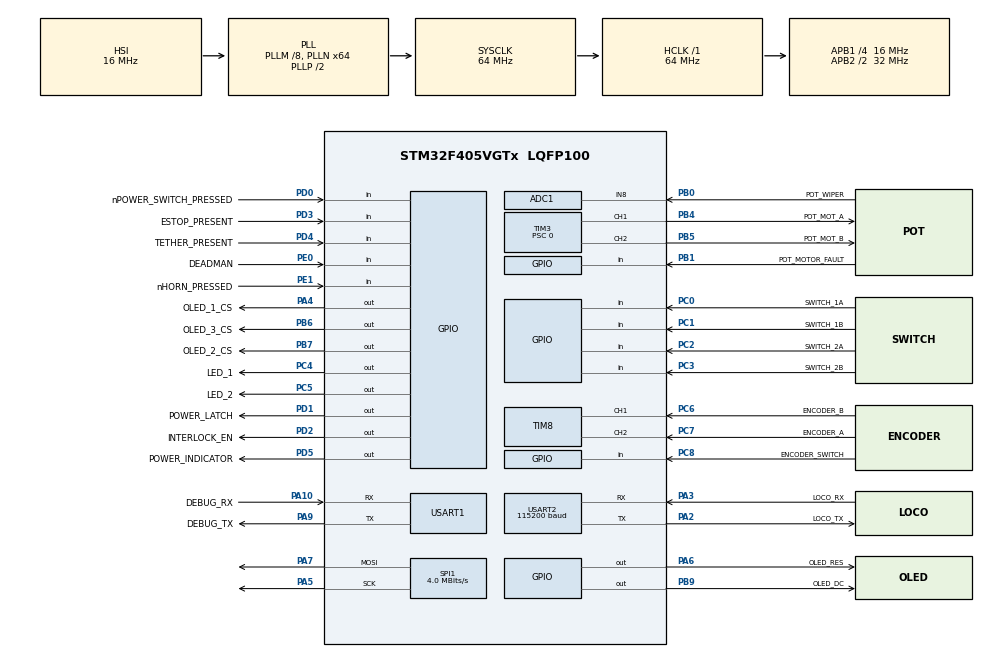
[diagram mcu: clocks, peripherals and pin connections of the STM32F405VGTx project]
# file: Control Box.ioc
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ADC1.Channel-0\#ChannelRegularConversion=ADC_CHANNEL_8
ADC1.ContinuousConvMode=ENABLE
ADC1.EOCSelection=ADC_EOC_SEQ_CONV
ADC1.NbrOfConversionFlag=1
ADC1.Rank-0\#ChannelRegularConversion=1
ADC1.SamplingTime-0\#ChannelRegularConversion=ADC_SAMPLETIME_3CYCLES
ADC1.master=1
Mcu.Family=STM32F4
Mcu.Name=STM32F405VGTx
Mcu.Package=LQFP100
NVIC.PriorityGroup=NVIC_PRIORITYGROUP_4
NVIC.USART1_IRQn=true\:0\:0\:false\:false\:true\:true\:true
NVIC.USART2_IRQn=true\:0\:0\:false\:false\:true\:true\:true
PA10.GPIO_Label=DEBUG_RX
PA10.Mode=Asynchronous
PA10.Signal=USART1_RX
PA2.GPIO_Label=LOCO_TX
PA2.Mode=Asynchronous
PA2.Signal=USART2_TX
PA3.GPIO_Label=LOCO_RX
PA3.Mode=Asynchronous
PA3.Signal=USART2_RX
PA4.GPIO_Label=OLED_1_CS
PA4.GPIO_PuPd=GPIO_NOPULL
PA4.PinState=GPIO_PIN_SET
PA4.Signal=GPIO_Output
PA5.Mode=TX_Only_Simplex_Unidirect_Master
PA5.Signal=SPI1_SCK
PA6.GPIO_Label=OLED_RES
PA6.GPIO_PuPd=GPIO_NOPULL
PA6.Signal=GPIO_Output
PA7.Mode=TX_Only_Simplex_Unidirect_Master
PA7.Signal=SPI1_MOSI
PA9.GPIO_Label=DEBUG_TX
PA9.Mode=Asynchronous
PA9.Signal=USART1_TX
PB0.GPIO_Label=POT_WIPER
PB0.Signal=SharedAnalog_PB0
PB1.GPIO_Label=POT_MOTOR_FAULT
PB1.Signal=GPIO_Input
PB4.GPIO_Label=POT_MOT_A
PB4.Signal=S_TIM3_CH1
PB5.GPIO_Label=POT_MOT_B
PB5.Signal=S_TIM3_CH2
PB6.GPIO_Label=OLED_3_CS
PB6.Signal=GPIO_Output
PB7.GPIO_Label=OLED_2_CS
PB7.Signal=GPIO_Output
PB9.GPIO_Label=OLED_DC
PB9.Signal=GPIO_Output
PC0.GPIO_Label=SWITCH_1A
PC0.Signal=GPIO_Input
PC1.GPIO_Label=SWITCH_1B
PC1.Signal=GPIO_Input
PC2.GPIO_Label=SWITCH_2A
PC2.Signal=GPIO_Input
PC3.GPIO_Label=SWITCH_2B
PC3.Signal=GPIO_Input
PC4.GPIO_Label=LED_1
PC4.Signal=GPIO_Output
PC5.GPIO_Label=LED_2
PC5.Signal=GPIO_Output
PC6.GPIO_Label=ENCODER_B
PC6.Signal=S_TIM8_CH1
PC7.GPIO_Label=ENCODER_A
PC7.Signal=S_TIM8_CH2
PC8.GPIO_Label=ENCODER_SWITCH
PC8.Signal=GPIO_Input
PD0.GPIO_Label=nPOWER_SWITCH_PRESSED
PD0.Signal=GPIO_Input
PD1.GPIO_Label=POWER_LATCH
PD1.Signal=GPIO_Output
PD2.GPIO_Label=INTERLOCK_EN
PD2.PinState=GPIO_PIN_RESET
PD2.Signal=GPIO_Output
PD3.GPIO_Label=ESTOP_PRESENT
PD3.Signal=GPIO_Input
PD4.GPIO_Label=TETHER_PRESENT
PD4.Signal=GPIO_Input
PD5.GPIO_Label=POWER_INDICATOR
PD5.Signal=GPIO_Output
PE0.GPIO_Label=DEADMAN
PE0.Signal=GPIO_Input
PE1.GPIO_Label=nHORN_PRESSED
PE1.Signal=GPIO_Input
ProjectManager.HeapSize=0x200
ProjectManager.StackSize=0x400
ProjectManager.TargetToolchain=STM32CubeIDE
RCC.48MHZClocksFreq_Value=32000000
RCC.AHBFreq_Value=64000000
RCC.APB1CLKDivider=RCC_HCLK_DIV4
RCC.APB1Freq_Value=16000000
RCC.APB1TimFreq_Value=32000000
RCC.APB2CLKDivider=RCC_HCLK_DIV2
RCC.APB2Freq_Value=32000000
RCC.APB2TimFreq_Value=64000000
RCC.CortexFreq_Value=64000000
RCC.HCLKFreq_Value=64000000
RCC.HSE_VALUE=25000000
RCC.HSI_VALUE=16000000
RCC.LSE_VALUE=32768
RCC.PLLM=8
RCC.PLLN=64
RCC.SYSCLKFreq_VALUE=64000000
RCC.SYSCLKSource=RCC_SYSCLKSOURCE_PLLCLK
RCC.VCOOutputFreq_Value=128000000
SH.S_TIM3_CH1.0=TIM3_CH1,PWM Generation1 CH1
SH.S_TIM3_CH2.0=TIM3_CH2,PWM Generation2 CH2
SH.S_TIM8_CH1.0=TIM8_CH1,Encoder_Interface
SH.S_TIM8_CH2.0=TIM8_CH2,Encoder_Interface
SH.SharedAnalog_PB0.0=GPIO_Analog
SH.SharedAnalog_PB0.1=ADC1_IN8,IN8
SPI1.BaudRatePrescaler=SPI_BAUDRATEPRESCALER_8
SPI1.CLKPhase=SPI_PHASE_1EDGE
SPI1.CalculateBaudRate=4.0 MBits/s
SPI1.Direction=SPI_DIRECTION_2LINES
SPI1.Mode=SPI_MODE_MASTER
SPI1.VirtualType=VM_MASTER
TIM3.AutoReloadPreload=TIM_AUTORELOAD_PRELOAD_DISABLE
TIM3.Channel-PWM\ Generation1\ CH1=TIM_CHANNEL_1
TIM3.Channel-PWM\ Generation2\ CH2=TIM_CHANNEL_2
TIM3.OCMode_PWM-PWM\ Generation1\ CH1=TIM_OCMODE_PWM1
TIM3.OCMode_PWM-PWM\ Generation2\ CH2=TIM_OCMODE_PWM1
TIM3.OCPolarity_1=TIM_OCPOLARITY_HIGH
TIM3.Period=4095
TIM3.Prescaler=0
TIM8.EncoderMode=TIM_ENCODERMODE_TI12
TIM8.IC1Filter=0
TIM8.IC1Polarity=TIM_ICPOLARITY_FALLING
TIM8.IC2Filter=0
TIM8.IC2Polarity=TIM_ICPOLARITY_RISING
USART1.VirtualMode=VM_ASYNC
USART2.BaudRate=115200
USART2.VirtualMode=VM_ASYNC
board=custom

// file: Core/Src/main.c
/* USER CODE BEGIN Header */
/**
 ******************************************************************************
 * @file           : main.c
 * @brief          : Main program body
 ******************************************************************************
 * @attention
 *
 * <h2><center>&copy; Copyright (c) 2021 STMicroelectronics.
 * All rights reserved.</center></h2>
 *
 * This software component is licensed by ST under BSD 3-Clause license,
 * the "License"; You may not use this file except in compliance with the
 * License. You may obtain a copy of the License at:
 *                        opensource.org/licenses/BSD-3-Clause
 *
 ******************************************************************************
 */
/* USER CODE END Header */
#include "main.h"

/* USER CODE BEGIN Includes */
#include "controlbox.hpp"
/* USER CODE END Includes */

ADC_HandleTypeDef hadc1;

SPI_HandleTypeDef hspi1;

TIM_HandleTypeDef htim3;
TIM_HandleTypeDef htim8;

UART_HandleTypeDef huart1;
UART_HandleTypeDef huart2;

void SystemClock_Config(void);
static void MX_GPIO_Init(void);
static void MX_SPI1_Init(void);
static void MX_TIM8_Init(void);
static void MX_ADC1_Init(void);
static void MX_USART2_UART_Init(void);
static void MX_TIM3_Init(void);
static void MX_USART1_UART_Init(void);

int main(void)
{

  /* MCU Configuration--------------------------------------------------------*/

  /* Reset of all peripherals, Initializes the Flash interface and the Systick. */
  HAL_Init();

  /* Configure the system clock */
  SystemClock_Config();

  /* Initialize all configured peripherals */
  MX_GPIO_Init();
  MX_SPI1_Init();
  MX_TIM8_Init();
  MX_ADC1_Init();
  MX_USART2_UART_Init();
  MX_TIM3_Init();
  MX_USART1_UART_Init();
  /* USER CODE BEGIN 2 */
	HAL_ADC_Start(&hadc1);

	HAL_TIM_Encoder_Start(&htim8, TIM_CHANNEL_ALL);

	HAL_TIM_PWM_Start(&htim3, TIM_CHANNEL_1);
	HAL_TIM_PWM_Start(&htim3, TIM_CHANNEL_2);

	init_input(&hadc1, &htim3);
	init_displays(&hspi1);
	init_modules(&huart2);

	control_box();
  /* USER CODE END 2 */

  /* Infinite loop */
	while (1) {

    /* USER CODE BEGIN 3 */
		// We shouldn't end up here unless something has gone wrong
		HAL_GPIO_WritePin(LED_2_GPIO_Port, LED_2_Pin, (GPIO_PinState) 1);
		HAL_Delay(500);
		HAL_GPIO_WritePin(LED_2_GPIO_Port, LED_2_Pin, (GPIO_PinState) 0);
		HAL_Delay(500);
	}
  /* USER CODE END 3 */
}

void SystemClock_Config(void)
{
  RCC_OscInitTypeDef RCC_OscInitStruct = {0};
  RCC_ClkInitTypeDef RCC_ClkInitStruct = {0};

  /** Configure the main internal regulator output voltage
  */
  __HAL_RCC_PWR_CLK_ENABLE();
  __HAL_PWR_VOLTAGESCALING_CONFIG(PWR_REGULATOR_VOLTAGE_SCALE1);
  /** Initializes the RCC Oscillators according to the specified parameters
  * in the RCC_OscInitTypeDef structure.
  */
  RCC_OscInitStruct.OscillatorType = RCC_OSCILLATORTYPE_HSI;
  RCC_OscInitStruct.HSIState = RCC_HSI_ON;
  RCC_OscInitStruct.HSICalibrationValue = RCC_HSICALIBRATION_DEFAULT;
  RCC_OscInitStruct.PLL.PLLState = RCC_PLL_ON;
  RCC_OscInitStruct.PLL.PLLSource = RCC_PLLSOURCE_HSI;
  RCC_OscInitStruct.PLL.PLLM = 8;
  RCC_OscInitStruct.PLL.PLLN = 64;
  RCC_OscInitStruct.PLL.PLLP = RCC_PLLP_DIV2;
  RCC_OscInitStruct.PLL.PLLQ = 4;
  if (HAL_RCC_OscConfig(&RCC_OscInitStruct) != HAL_OK)
  {
    Error_Handler();
  }
  /** Initializes the CPU, AHB and APB buses clocks
  */
  RCC_ClkInitStruct.ClockType = RCC_CLOCKTYPE_HCLK|RCC_CLOCKTYPE_SYSCLK
                              |RCC_CLOCKTYPE_PCLK1|RCC_CLOCKTYPE_PCLK2;
  RCC_ClkInitStruct.SYSCLKSource = RCC_SYSCLKSOURCE_PLLCLK;
  RCC_ClkInitStruct.AHBCLKDivider = RCC_SYSCLK_DIV1;
  RCC_ClkInitStruct.APB1CLKDivider = RCC_HCLK_DIV4;
  RCC_ClkInitStruct.APB2CLKDivider = RCC_HCLK_DIV2;

  if (HAL_RCC_ClockConfig(&RCC_ClkInitStruct, FLASH_LATENCY_2) != HAL_OK)
  {
    Error_Handler();
  }
}

static void MX_ADC1_Init(void)
{

  ADC_ChannelConfTypeDef sConfig = {0};

  /** Configure the global features of the ADC (Clock, Resolution, Data Alignment and number of conversion)
  */
  hadc1.Instance = ADC1;
  hadc1.Init.ClockPrescaler = ADC_CLOCK_SYNC_PCLK_DIV2;
  hadc1.Init.Resolution = ADC_RESOLUTION_12B;
  hadc1.Init.ScanConvMode = DISABLE;
  hadc1.Init.ContinuousConvMode = ENABLE;
  hadc1.Init.DiscontinuousConvMode = DISABLE;
  hadc1.Init.ExternalTrigConvEdge = ADC_EXTERNALTRIGCONVEDGE_NONE;
  hadc1.Init.ExternalTrigConv = ADC_SOFTWARE_START;
  hadc1.Init.DataAlign = ADC_DATAALIGN_RIGHT;
  hadc1.Init.NbrOfConversion = 1;
  hadc1.Init.DMAContinuousRequests = DISABLE;
  hadc1.Init.EOCSelection = ADC_EOC_SEQ_CONV;
  if (HAL_ADC_Init(&hadc1) != HAL_OK)
  {
    Error_Handler();
  }
  /** Configure for the selected ADC regular channel its corresponding rank in the sequencer and its sample time.
  */
  sConfig.Channel = ADC_CHANNEL_8;
  sConfig.Rank = 1;
  sConfig.SamplingTime = ADC_SAMPLETIME_3CYCLES;
  if (HAL_ADC_ConfigChannel(&hadc1, &sConfig) != HAL_OK)
  {
    Error_Handler();
  }

}

static void MX_SPI1_Init(void)
{

  /* SPI1 parameter configuration*/
  hspi1.Instance = SPI1;
  hspi1.Init.Mode = SPI_MODE_MASTER;
  hspi1.Init.Direction = SPI_DIRECTION_2LINES;
  hspi1.Init.DataSize = SPI_DATASIZE_8BIT;
  hspi1.Init.CLKPolarity = SPI_POLARITY_LOW;
  hspi1.Init.CLKPhase = SPI_PHASE_1EDGE;
  hspi1.Init.NSS = SPI_NSS_SOFT;
  hspi1.Init.BaudRatePrescaler = SPI_BAUDRATEPRESCALER_8;
  hspi1.Init.FirstBit = SPI_FIRSTBIT_MSB;
  hspi1.Init.TIMode = SPI_TIMODE_DISABLE;
  hspi1.Init.CRCCalculation = SPI_CRCCALCULATION_DISABLE;
  hspi1.Init.CRCPolynomial = 10;
  if (HAL_SPI_Init(&hspi1) != HAL_OK)
  {
    Error_Handler();
  }

}

static void MX_TIM3_Init(void)
{

  TIM_MasterConfigTypeDef sMasterConfig = {0};
  TIM_OC_InitTypeDef sConfigOC = {0};

  htim3.Instance = TIM3;
  htim3.Init.Prescaler = 0;
  htim3.Init.CounterMode = TIM_COUNTERMODE_UP;
  htim3.Init.Period = 4095;
  htim3.Init.ClockDivision = TIM_CLOCKDIVISION_DIV1;
  htim3.Init.AutoReloadPreload = TIM_AUTORELOAD_PRELOAD_DISABLE;
  if (HAL_TIM_PWM_Init(&htim3) != HAL_OK)
  {
    Error_Handler();
  }
  sMasterConfig.MasterOutputTrigger = TIM_TRGO_RESET;
  sMasterConfig.MasterSlaveMode = TIM_MASTERSLAVEMODE_DISABLE;
  if (HAL_TIMEx_MasterConfigSynchronization(&htim3, &sMasterConfig) != HAL_OK)
  {
    Error_Handler();
  }
  sConfigOC.OCMode = TIM_OCMODE_PWM1;
  sConfigOC.Pulse = 0;
  sConfigOC.OCPolarity = TIM_OCPOLARITY_HIGH;
  sConfigOC.OCFastMode = TIM_OCFAST_DISABLE;
  if (HAL_TIM_PWM_ConfigChannel(&htim3, &sConfigOC, TIM_CHANNEL_1) != HAL_OK)
  {
    Error_Handler();
  }
  if (HAL_TIM_PWM_ConfigChannel(&htim3, &sConfigOC, TIM_CHANNEL_2) != HAL_OK)
  {
    Error_Handler();
  }
  HAL_TIM_MspPostInit(&htim3);

}

static void MX_TIM8_Init(void)
{

  TIM_Encoder_InitTypeDef sConfig = {0};
  TIM_MasterConfigTypeDef sMasterConfig = {0};

  htim8.Instance = TIM8;
  htim8.Init.Prescaler = 0;
  htim8.Init.CounterMode = TIM_COUNTERMODE_UP;
  htim8.Init.Period = 65535;
  htim8.Init.ClockDivision = TIM_CLOCKDIVISION_DIV1;
  htim8.Init.RepetitionCounter = 0;
  htim8.Init.AutoReloadPreload = TIM_AUTORELOAD_PRELOAD_DISABLE;
  sConfig.EncoderMode = TIM_ENCODERMODE_TI12;
  sConfig.IC1Polarity = TIM_ICPOLARITY_FALLING;
  sConfig.IC1Selection = TIM_ICSELECTION_DIRECTTI;
  sConfig.IC1Prescaler = TIM_ICPSC_DIV1;
  sConfig.IC1Filter = 0;
  sConfig.IC2Polarity = TIM_ICPOLARITY_RISING;
  sConfig.IC2Selection = TIM_ICSELECTION_DIRECTTI;
  sConfig.IC2Prescaler = TIM_ICPSC_DIV1;
  sConfig.IC2Filter = 0;
  if (HAL_TIM_Encoder_Init(&htim8, &sConfig) != HAL_OK)
  {
    Error_Handler();
  }
  sMasterConfig.MasterOutputTrigger = TIM_TRGO_RESET;
  sMasterConfig.MasterSlaveMode = TIM_MASTERSLAVEMODE_DISABLE;
  if (HAL_TIMEx_MasterConfigSynchronization(&htim8, &sMasterConfig) != HAL_OK)
  {
    Error_Handler();
  }

}

static void MX_USART1_UART_Init(void)
{

  huart1.Instance = USART1;
  huart1.Init.BaudRate = 115200;
  huart1.Init.WordLength = UART_WORDLENGTH_8B;
  huart1.Init.StopBits = UART_STOPBITS_1;
  huart1.Init.Parity = UART_PARITY_NONE;
  huart1.Init.Mode = UART_MODE_TX_RX;
  huart1.Init.HwFlowCtl = UART_HWCONTROL_NONE;
  huart1.Init.OverSampling = UART_OVERSAMPLING_16;
  if (HAL_UART_Init(&huart1) != HAL_OK)
  {
    Error_Handler();
  }

}

static void MX_USART2_UART_Init(void)
{

  huart2.Instance = USART2;
  huart2.Init.BaudRate = 115200;
  huart2.Init.WordLength = UART_WORDLENGTH_8B;
  huart2.Init.StopBits = UART_STOPBITS_1;
  huart2.Init.Parity = UART_PARITY_NONE;
  huart2.Init.Mode = UART_MODE_TX_RX;
  huart2.Init.HwFlowCtl = UART_HWCONTROL_NONE;
  huart2.Init.OverSampling = UART_OVERSAMPLING_16;
  if (HAL_UART_Init(&huart2) != HAL_OK)
  {
    Error_Handler();
  }

}

static void MX_GPIO_Init(void)
{
  GPIO_InitTypeDef GPIO_InitStruct = {0};

  /* GPIO Ports Clock Enable */
  __HAL_RCC_GPIOC_CLK_ENABLE();
  __HAL_RCC_GPIOA_CLK_ENABLE();
  __HAL_RCC_GPIOB_CLK_ENABLE();
  __HAL_RCC_GPIOD_CLK_ENABLE();
  __HAL_RCC_GPIOE_CLK_ENABLE();

  /*Configure GPIO pin Output Level */
  HAL_GPIO_WritePin(OLED_1_CS_GPIO_Port, OLED_1_CS_Pin, GPIO_PIN_SET);

  /*Configure GPIO pin Output Level */
  HAL_GPIO_WritePin(OLED_RES_GPIO_Port, OLED_RES_Pin, GPIO_PIN_RESET);

  /*Configure GPIO pin Output Level */
  HAL_GPIO_WritePin(GPIOC, LED_1_Pin|LED_2_Pin, GPIO_PIN_RESET);

  /*Configure GPIO pin Output Level */
  HAL_GPIO_WritePin(GPIOD, POWER_LATCH_Pin|INTERLOCK_EN_Pin|POWER_INDICATOR_Pin, GPIO_PIN_RESET);

  /*Configure GPIO pin Output Level */
  HAL_GPIO_WritePin(GPIOB, OLED_3_CS_Pin|OLED_2_CS_Pin|OLED_DC_Pin, GPIO_PIN_RESET);

  /*Configure GPIO pins : SWITCH_1A_Pin SWITCH_1B_Pin SWITCH_2A_Pin SWITCH_2B_Pin
                           ENCODER_SWITCH_Pin */
  GPIO_InitStruct.Pin = SWITCH_1A_Pin|SWITCH_1B_Pin|SWITCH_2A_Pin|SWITCH_2B_Pin
                          |ENCODER_SWITCH_Pin;
  GPIO_InitStruct.Mode = GPIO_MODE_INPUT;
  GPIO_InitStruct.Pull = GPIO_NOPULL;
  HAL_GPIO_Init(GPIOC, &GPIO_InitStruct);

  /*Configure GPIO pins : OLED_1_CS_Pin OLED_RES_Pin */
  GPIO_InitStruct.Pin = OLED_1_CS_Pin|OLED_RES_Pin;
  GPIO_InitStruct.Mode = GPIO_MODE_OUTPUT_PP;
  GPIO_InitStruct.Pull = GPIO_NOPULL;
  GPIO_InitStruct.Speed = GPIO_SPEED_FREQ_LOW;
  HAL_GPIO_Init(GPIOA, &GPIO_InitStruct);

  /*Configure GPIO pins : LED_1_Pin LED_2_Pin */
  GPIO_InitStruct.Pin = LED_1_Pin|LED_2_Pin;
  GPIO_InitStruct.Mode = GPIO_MODE_OUTPUT_PP;
  GPIO_InitStruct.Pull = GPIO_NOPULL;
  GPIO_InitStruct.Speed = GPIO_SPEED_FREQ_LOW;
  HAL_GPIO_Init(GPIOC, &GPIO_InitStruct);

  /*Configure GPIO pin : POT_MOTOR_FAULT_Pin */
  GPIO_InitStruct.Pin = POT_MOTOR_FAULT_Pin;
  GPIO_InitStruct.Mode = GPIO_MODE_INPUT;
  GPIO_InitStruct.Pull = GPIO_NOPULL;
  HAL_GPIO_Init(POT_MOTOR_FAULT_GPIO_Port, &GPIO_InitStruct);

  /*Configure GPIO pins : nPOWER_SWITCH_PRESSED_Pin ESTOP_PRESENT_Pin TETHER_PRESENT_Pin */
  GPIO_InitStruct.Pin = nPOWER_SWITCH_PRESSED_Pin|ESTOP_PRESENT_Pin|TETHER_PRESENT_Pin;
  GPIO_InitStruct.Mode = GPIO_MODE_INPUT;
  GPIO_InitStruct.Pull = GPIO_NOPULL;
  HAL_GPIO_Init(GPIOD, &GPIO_InitStruct);

  /*Configure GPIO pins : POWER_LATCH_Pin INTERLOCK_EN_Pin POWER_INDICATOR_Pin */
  GPIO_InitStruct.Pin = POWER_LATCH_Pin|INTERLOCK_EN_Pin|POWER_INDICATOR_Pin;
  GPIO_InitStruct.Mode = GPIO_MODE_OUTPUT_PP;
  GPIO_InitStruct.Pull = GPIO_NOPULL;
  GPIO_InitStruct.Speed = GPIO_SPEED_FREQ_LOW;
  HAL_GPIO_Init(GPIOD, &GPIO_InitStruct);

  /*Configure GPIO pins : OLED_3_CS_Pin OLED_2_CS_Pin OLED_DC_Pin */
  GPIO_InitStruct.Pin = OLED_3_CS_Pin|OLED_2_CS_Pin|OLED_DC_Pin;
  GPIO_InitStruct.Mode = GPIO_MODE_OUTPUT_PP;
  GPIO_InitStruct.Pull = GPIO_NOPULL;
  GPIO_InitStruct.Speed = GPIO_SPEED_FREQ_LOW;
  HAL_GPIO_Init(GPIOB, &GPIO_InitStruct);

  /*Configure GPIO pins : DEADMAN_Pin nHORN_PRESSED_Pin */
  GPIO_InitStruct.Pin = DEADMAN_Pin|nHORN_PRESSED_Pin;
  GPIO_InitStruct.Mode = GPIO_MODE_INPUT;
  GPIO_InitStruct.Pull = GPIO_NOPULL;
  HAL_GPIO_Init(GPIOE, &GPIO_InitStruct);

}

void Error_Handler(void)
{
	__disable_irq();
	while (1) {
	}
}

/************************ (C) COPYRIGHT STMicroelectronics *****END OF FILE****/
